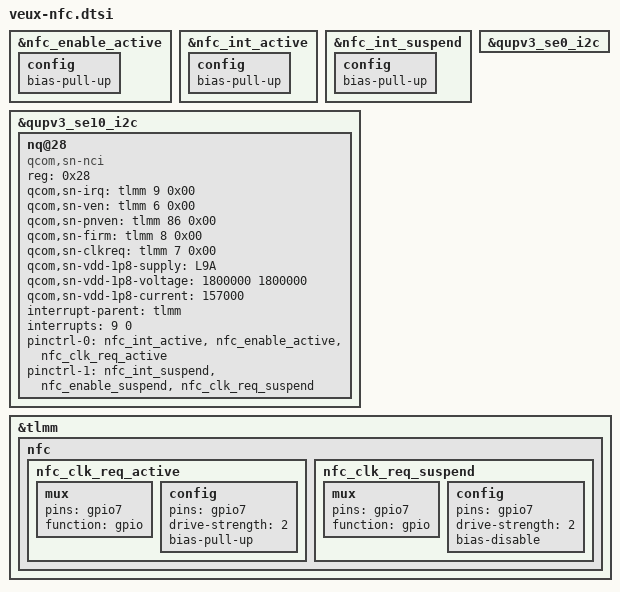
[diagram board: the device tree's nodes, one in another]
&nfc_enable_active {
	config {
		/delete-property/ bias-disable;
		bias-pull-up;
	};
};

&nfc_int_active {
	config {
		/delete-property/ bias-pull-down;
		bias-pull-up;
	};
};

&nfc_int_suspend {
	config {
		/delete-property/ bias-pull-down;
		bias-pull-up;
	};
};

&qupv3_se0_i2c {
	/delete-node/ nq@28;
};

&qupv3_se10_i2c {
	nq@28 {
		compatible = "qcom,sn-nci";
		reg = <0x28>;
		qcom,sn-irq = <&tlmm 9 0x00>;
		qcom,sn-ven = <&tlmm 6 0x00>;
		qcom,sn-pnven = <&tlmm 86 0x00>;
		qcom,sn-firm = <&tlmm 8 0x00>;
		qcom,sn-clkreq = <&tlmm 7 0x00>;
		qcom,sn-vdd-1p8-supply = <&L9A>;
		qcom,sn-vdd-1p8-voltage = <1800000 1800000>;
		qcom,sn-vdd-1p8-current = <157000>;
		interrupt-parent = <&tlmm>;
		interrupts = <9 0>;
		interrupt-names = "nfc_irq";
		pinctrl-names = "nfc_active", "nfc_suspend";
		pinctrl-0 = <&nfc_int_active &nfc_enable_active &nfc_clk_req_active>;
		pinctrl-1 = <&nfc_int_suspend &nfc_enable_suspend &nfc_clk_req_suspend>;
	};
};

&tlmm {
	nfc {
		nfc_clk_req_active: nfc_clk_req_active {
			mux {
				pins = "gpio7";
				function = "gpio";
			};

			config {
				pins = "gpio7";
				drive-strength = <2>;
				bias-pull-up;
			};
		};

		nfc_clk_req_suspend: nfc_clk_req_suspend {
			mux {
				pins = "gpio7";
				function = "gpio";
			};

			config {
				pins = "gpio7";
				drive-strength = <2>;
				bias-disable;
			};
		};
	};
};
